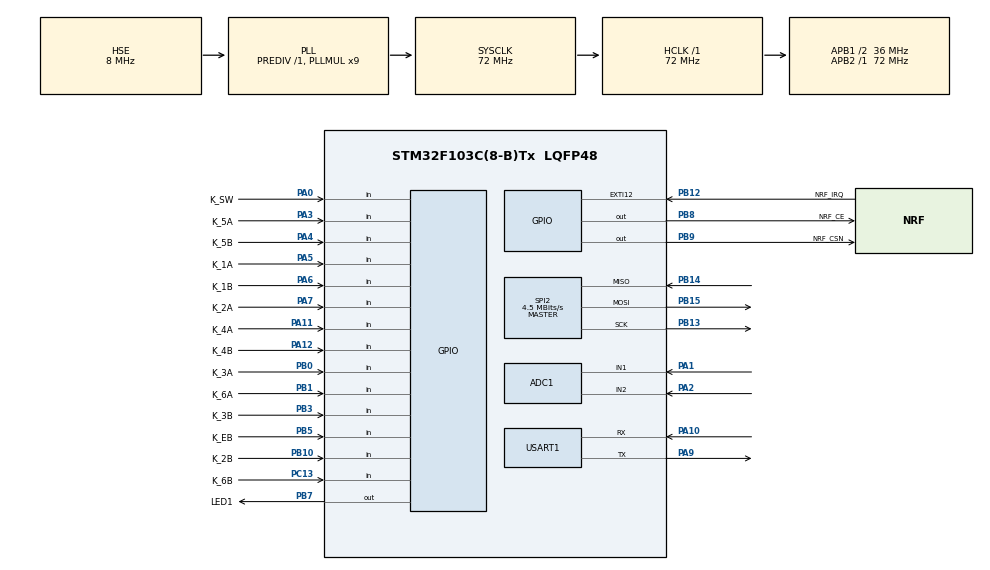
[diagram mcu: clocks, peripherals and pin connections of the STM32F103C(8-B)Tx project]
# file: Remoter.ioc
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ADC1.Channel-0\#ChannelRegularConversion=ADC_CHANNEL_1
ADC1.ExternalTrigConv=ADC_SOFTWARE_START
ADC1.NbrOfConversionFlag=1
ADC1.Rank-0\#ChannelRegularConversion=1
ADC1.SamplingTime-0\#ChannelRegularConversion=ADC_SAMPLETIME_71CYCLES_5
ADC1.master=1
FREERTOS.INCLUDE_vTaskDelayUntil=1
FREERTOS.Tasks01=Remoter_Task,0,512,Remoter_Main,As weak,NULL,Dynamic,NULL,NULL
Mcu.Family=STM32F1
Mcu.Name=STM32F103C(8-B)Tx
Mcu.Package=LQFP48
NVIC.EXTI15_10_IRQn=true\:5\:0\:false\:false\:true\:true\:true\:true\:true
NVIC.PriorityGroup=NVIC_PRIORITYGROUP_4
NVIC.TIM4_IRQn=true\:15\:0\:false\:false\:true\:false\:false\:true\:true
NVIC.TimeBase=TIM4_IRQn
NVIC.TimeBaseIP=TIM4
NVIC.USART1_IRQn=true\:5\:0\:false\:false\:true\:true\:true\:true\:true
PA0-WKUP.GPIO_Label=K_SW
PA0-WKUP.GPIO_PuPd=GPIO_PULLUP
PA0-WKUP.Signal=GPIO_Input
PA1.Signal=ADCx_IN1
PA10.Mode=Asynchronous
PA10.Signal=USART1_RX
PA11.GPIO_Label=K_4A
PA11.GPIO_PuPd=GPIO_PULLUP
PA11.Signal=GPIO_Input
PA12.GPIO_Label=K_4B
PA12.GPIO_PuPd=GPIO_PULLUP
PA12.Signal=GPIO_Input
PA13.Mode=Serial_Wire
PA13.Signal=SYS_JTMS-SWDIO
PA14.Mode=Serial_Wire
PA14.Signal=SYS_JTCK-SWCLK
PA2.Signal=ADCx_IN2
PA3.GPIO_Label=K_5A
PA3.GPIO_PuPd=GPIO_PULLUP
PA3.Signal=GPIO_Input
PA4.GPIO_Label=K_5B
PA4.GPIO_PuPd=GPIO_PULLUP
PA4.Signal=GPIO_Input
PA5.GPIO_Label=K_1A
PA5.GPIO_PuPd=GPIO_PULLUP
PA5.Signal=GPIO_Input
PA6.GPIO_Label=K_1B
PA6.GPIO_PuPd=GPIO_PULLUP
PA6.Signal=GPIO_Input
PA7.GPIO_Label=K_2A
PA7.GPIO_PuPd=GPIO_PULLUP
PA7.Signal=GPIO_Input
PA9.Mode=Asynchronous
PA9.Signal=USART1_TX
PB0.GPIO_Label=K_3A
PB0.GPIO_PuPd=GPIO_PULLUP
PB0.Signal=GPIO_Input
PB1.GPIO_Label=K_6A
PB1.GPIO_PuPd=GPIO_PULLUP
PB1.Signal=GPIO_Input
PB10.GPIO_Label=K_2B
PB10.GPIO_PuPd=GPIO_PULLUP
PB10.Signal=GPIO_Input
PB12.GPIO_Label=NRF_IRQ
PB12.GPIO_ModeDefaultEXTI=GPIO_MODE_IT_FALLING
PB12.GPIO_PuPd=GPIO_PULLUP
PB12.Signal=GPXTI12
PB13.Mode=Full_Duplex_Master
PB13.Signal=SPI2_SCK
PB14.Mode=Full_Duplex_Master
PB14.Signal=SPI2_MISO
PB15.Mode=Full_Duplex_Master
PB15.Signal=SPI2_MOSI
PB3.GPIO_Label=K_3B
PB3.GPIO_PuPd=GPIO_PULLUP
PB3.Signal=GPIO_Input
PB5.GPIO_Label=K_EB
PB5.GPIO_PuPd=GPIO_PULLUP
PB5.Signal=GPIO_Input
PB7.GPIO_Label=LED1
PB7.Signal=GPIO_Output
PB8.GPIO_Label=NRF_CE
PB8.Signal=GPIO_Output
PB9.GPIO_Label=NRF_CSN
PB9.Signal=GPIO_Output
PC13-TAMPER-RTC.GPIO_Label=K_6B
PC13-TAMPER-RTC.GPIO_PuPd=GPIO_PULLUP
PC13-TAMPER-RTC.Signal=GPIO_Input
PD0-OSC_IN.Mode=HSE-External-Oscillator
PD0-OSC_IN.Signal=RCC_OSC_IN
PD1-OSC_OUT.Mode=HSE-External-Oscillator
PD1-OSC_OUT.Signal=RCC_OSC_OUT
ProjectManager.HeapSize=0x200
ProjectManager.StackSize=0x400
ProjectManager.TargetToolchain=CMake
RCC.ADCPresc=RCC_ADCPCLK2_DIV6
RCC.AHBFreq_Value=72000000
RCC.APB1CLKDivider=RCC_HCLK_DIV2
RCC.APB1Freq_Value=36000000
RCC.APB1TimFreq_Value=72000000
RCC.APB2Freq_Value=72000000
RCC.APB2TimFreq_Value=72000000
RCC.HCLKFreq_Value=72000000
RCC.PLLMUL=RCC_PLL_MUL9
RCC.PLLSourceVirtual=RCC_PLLSOURCE_HSE
RCC.SYSCLKFreq_VALUE=72000000
RCC.SYSCLKSource=RCC_SYSCLKSOURCE_PLLCLK
RCC.USBFreq_Value=72000000
SH.ADCx_IN1.0=ADC1_IN1,IN1
SH.ADCx_IN2.0=ADC1_IN2,IN2
SPI2.BaudRatePrescaler=SPI_BAUDRATEPRESCALER_8
SPI2.CalculateBaudRate=4.5 MBits/s
SPI2.Direction=SPI_DIRECTION_2LINES
SPI2.Mode=SPI_MODE_MASTER
SPI2.VirtualType=VM_MASTER
USART1.VirtualMode=VM_ASYNC
VP_FREERTOS_VS_CMSIS_V1.Mode=CMSIS_V1
VP_SYS_VS_tim4.Mode=TIM4
VP_TIM1_VS_ClockSourceINT.Mode=Internal
board=custom

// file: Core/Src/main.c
/* USER CODE BEGIN Header */
/**
  ******************************************************************************
  * @file           : main.c
  * @brief          : Main program body
  ******************************************************************************
  * @attention
  *
  * Copyright (c) 2026 STMicroelectronics.
  * All rights reserved.
  *
  * This software is licensed under terms that can be found in the LICENSE file
  * in the root directory of this software component.
  * If no LICENSE file comes with this software, it is provided AS-IS.
  *
  ******************************************************************************
  */
/* USER CODE END Header */
#include "main.h"
#include "cmsis_os.h"
#include "adc.h"
#include "spi.h"
#include "tim.h"
#include "usart.h"
#include "gpio.h"

void SystemClock_Config(void);
void MX_FREERTOS_Init(void);

int main(void)
{

  /* MCU Configuration--------------------------------------------------------*/

  /* Reset of all peripherals, Initializes the Flash interface and the Systick. */
  HAL_Init();

  /* Configure the system clock */
  SystemClock_Config();

  /* Initialize all configured peripherals */
  MX_GPIO_Init();
  MX_ADC1_Init();
  MX_SPI2_Init();
  MX_USART1_UART_Init();
  MX_TIM1_Init();
  /* USER CODE BEGIN 2 */
  /* NVIC 使能（EXTI15_10=nRF24 IRQ、USART1=日志收，均优先级 5）由 CubeMX
   * 受管生成在 gpio.c / usart.c，此处不再手添（免双源真相） */
  /* USER CODE END 2 */

  /* Call init function for freertos objects (in cmsis_os2.c) */
  MX_FREERTOS_Init();

  /* Start scheduler */
  osKernelStart();

  /* We should never get here as control is now taken by the scheduler */

  /* Infinite loop */
  while (1)
  {

  }
}

void SystemClock_Config(void)
{
  RCC_OscInitTypeDef RCC_OscInitStruct = {0};
  RCC_ClkInitTypeDef RCC_ClkInitStruct = {0};
  RCC_PeriphCLKInitTypeDef PeriphClkInit = {0};

  /** Initializes the RCC Oscillators according to the specified parameters
  * in the RCC_OscInitTypeDef structure.
  */
  RCC_OscInitStruct.OscillatorType = RCC_OSCILLATORTYPE_HSE;
  RCC_OscInitStruct.HSEState = RCC_HSE_ON;
  RCC_OscInitStruct.HSEPredivValue = RCC_HSE_PREDIV_DIV1;
  RCC_OscInitStruct.HSIState = RCC_HSI_ON;
  RCC_OscInitStruct.PLL.PLLState = RCC_PLL_ON;
  RCC_OscInitStruct.PLL.PLLSource = RCC_PLLSOURCE_HSE;
  RCC_OscInitStruct.PLL.PLLMUL = RCC_PLL_MUL9;
  if (HAL_RCC_OscConfig(&RCC_OscInitStruct) != HAL_OK)
  {
    Error_Handler();
  }

  /** Initializes the CPU, AHB and APB buses clocks
  */
  RCC_ClkInitStruct.ClockType = RCC_CLOCKTYPE_HCLK|RCC_CLOCKTYPE_SYSCLK
                              |RCC_CLOCKTYPE_PCLK1|RCC_CLOCKTYPE_PCLK2;
  RCC_ClkInitStruct.SYSCLKSource = RCC_SYSCLKSOURCE_PLLCLK;
  RCC_ClkInitStruct.AHBCLKDivider = RCC_SYSCLK_DIV1;
  RCC_ClkInitStruct.APB1CLKDivider = RCC_HCLK_DIV2;
  RCC_ClkInitStruct.APB2CLKDivider = RCC_HCLK_DIV1;

  if (HAL_RCC_ClockConfig(&RCC_ClkInitStruct, FLASH_LATENCY_2) != HAL_OK)
  {
    Error_Handler();
  }
  PeriphClkInit.PeriphClockSelection = RCC_PERIPHCLK_ADC;
  PeriphClkInit.AdcClockSelection = RCC_ADCPCLK2_DIV6;
  if (HAL_RCCEx_PeriphCLKConfig(&PeriphClkInit) != HAL_OK)
  {
    Error_Handler();
  }
}

void HAL_TIM_PeriodElapsedCallback(TIM_HandleTypeDef *htim)
{
  if (htim->Instance == TIM4)
  {
    HAL_IncTick();
  }
}

void Error_Handler(void)
{
  __disable_irq();
  while (1)
  {
  }
}

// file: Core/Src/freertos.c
/* USER CODE BEGIN Header */
/**
  ******************************************************************************
  * File Name          : freertos.c
  * Description        : Code for freertos applications
  ******************************************************************************
  * @attention
  *
  * Copyright (c) 2026 STMicroelectronics.
  * All rights reserved.
  *
  * This software is licensed under terms that can be found in the LICENSE file
  * in the root directory of this software component.
  * If no LICENSE file comes with this software, it is provided AS-IS.
  *
  ******************************************************************************
  */
/* USER CODE END Header */

#include "FreeRTOS.h"
#include "task.h"
#include "main.h"
#include "cmsis_os.h"

osThreadId Remoter_TaskHandle;

void Remoter_Main(void const * argument);

void MX_FREERTOS_Init(void); /* (MISRA C 2004 rule 8.1) */

/* GetIdleTaskMemory prototype (linked to static allocation support) */
void vApplicationGetIdleTaskMemory( StaticTask_t **ppxIdleTaskTCBBuffer, StackType_t **ppxIdleTaskStackBuffer, uint32_t *pulIdleTaskStackSize );

/* USER CODE BEGIN GET_IDLE_TASK_MEMORY */
static StaticTask_t xIdleTaskTCBBuffer;
static StackType_t xIdleStack[configMINIMAL_STACK_SIZE];

void vApplicationGetIdleTaskMemory( StaticTask_t **ppxIdleTaskTCBBuffer, StackType_t **ppxIdleTaskStackBuffer, uint32_t *pulIdleTaskStackSize )
{
  *ppxIdleTaskTCBBuffer = &xIdleTaskTCBBuffer;
  *ppxIdleTaskStackBuffer = &xIdleStack[0];
  *pulIdleTaskStackSize = configMINIMAL_STACK_SIZE;
  /* place for user code */
}
/* USER CODE END GET_IDLE_TASK_MEMORY */

void MX_FREERTOS_Init(void) {

  /* Create the thread(s) */
  /* definition and creation of Remoter_Task */
  osThreadDef(Remoter_Task, Remoter_Main, osPriorityNormal, 0, 512);
  Remoter_TaskHandle = osThreadCreate(osThread(Remoter_Task), NULL);

}

__weak void Remoter_Main(void const * argument)
{
  for(;;)
  {
    osDelay(1);
  }
}
